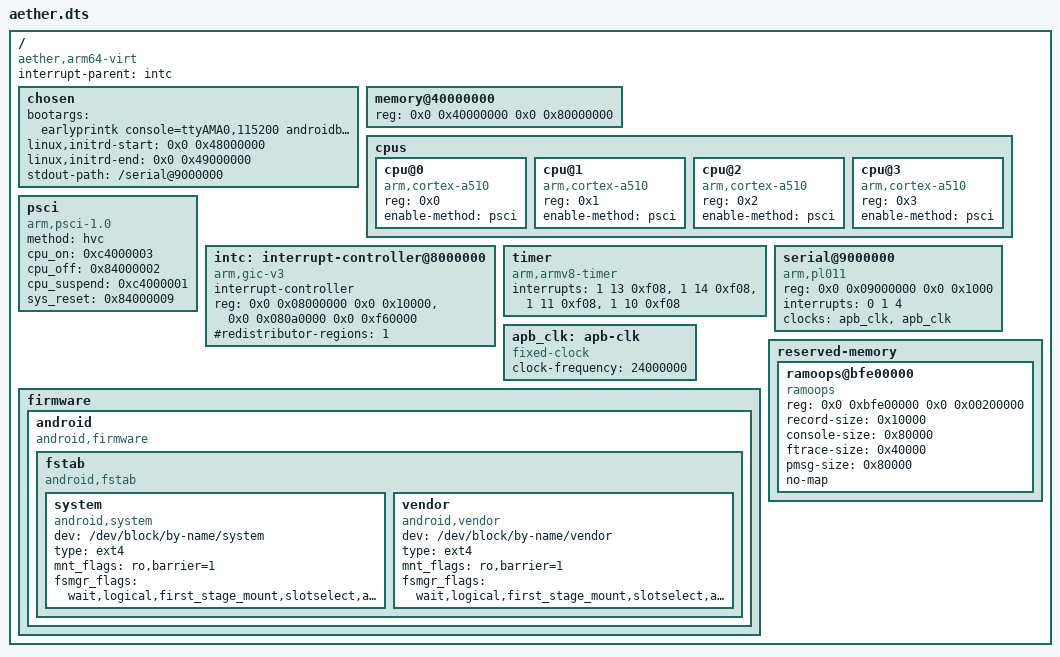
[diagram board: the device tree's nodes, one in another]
/* aether.dts — AETHER Android device tree source.
 *
 * Mirrors hypervisor/src/kernel.rs::build_production_android_dtb() output
 * with extras from hypervisor/src/kernel_defconfig.rs::ProductionDtbExtras
 * ::aether_defaults().
 *
 * Memory map matches QEMU virt machine (ARM tier). Snapdragon X Elite tier
 * uses the same layout but uart_clock_hz = 7_372_800 and the SoC's GICv3
 * base addresses.
 *
 * Source: source.android.com/devices/architecture/dto
 *         Documentation/devicetree/bindings/ in mainline kernel
 */

/dts-v1/;

/ {
    compatible = "aether,arm64-virt", "linux,dummy-virt";
    interrupt-parent = <&intc>;
    #address-cells = <2>;
    #size-cells = <2>;

    chosen {
        bootargs = "earlyprintk console=ttyAMA0,115200 androidboot.hardware=aether androidboot.selinux=enforcing androidboot.verifiedbootstate=green";
        linux,initrd-start = <0x0 0x48000000>;   /* ProductionDtbExtras.initrd_start_ipa */
        linux,initrd-end   = <0x0 0x49000000>;   /* ProductionDtbExtras.initrd_end_ipa   */
        stdout-path = "/serial@9000000";
    };

    memory@40000000 {
        device_type = "memory";
        reg = <0x0 0x40000000 0x0 0x80000000>;   /* 2 GiB DRAM at 0x40000000 */
    };

    cpus {
        #address-cells = <1>;
        #size-cells = <0>;

        cpu@0 {
            device_type = "cpu";
            compatible = "arm,cortex-a510";
            reg = <0x0>;
            enable-method = "psci";
        };
        cpu@1 {
            device_type = "cpu";
            compatible = "arm,cortex-a510";
            reg = <0x1>;
            enable-method = "psci";
        };
        cpu@2 {
            device_type = "cpu";
            compatible = "arm,cortex-a510";
            reg = <0x2>;
            enable-method = "psci";
        };
        cpu@3 {
            device_type = "cpu";
            compatible = "arm,cortex-a510";
            reg = <0x3>;
            enable-method = "psci";
        };
    };

    psci {
        compatible = "arm,psci-1.0";
        method = "hvc";
        cpu_on   = <0xc4000003>;
        cpu_off  = <0x84000002>;
        cpu_suspend = <0xc4000001>;
        sys_reset = <0x84000009>;
    };

    intc: interrupt-controller@8000000 {
        compatible = "arm,gic-v3";
        #interrupt-cells = <3>;
        interrupt-controller;
        reg = <0x0 0x08000000 0x0 0x10000>,   /* GICD */
              <0x0 0x080a0000 0x0 0xf60000>;  /* GICR — sized per ch10 */
        #redistributor-regions = <1>;
    };

    timer {
        compatible = "arm,armv8-timer";
        interrupts = <1 13 0xf08>,            /* sec PPI 13 */
                     <1 14 0xf08>,            /* non-sec PPI 14 */
                     <1 11 0xf08>,            /* virt PPI 11 */
                     <1 10 0xf08>;            /* hyp PPI 10 */
    };

    serial@9000000 {
        compatible = "arm,pl011", "arm,primecell";
        reg = <0x0 0x09000000 0x0 0x1000>;
        interrupts = <0 1 4>;                 /* SPI 1, level-high */
        clocks = <&apb_clk>, <&apb_clk>;
        clock-names = "uartclk", "apb_pclk";
    };

    apb_clk: apb-clk {
        compatible = "fixed-clock";
        #clock-cells = <0>;
        clock-frequency = <24000000>;         /* ProductionDtbExtras.uart_clock_hz */
    };

    firmware {
        android {
            compatible = "android,firmware";

            fstab {
                compatible = "android,fstab";

                system {
                    compatible = "android,system";
                    dev = "/dev/block/by-name/system";
                    type = "ext4";
                    mnt_flags = "ro,barrier=1";
                    fsmgr_flags = "wait,logical,first_stage_mount,slotselect,avb=vbmeta";
                };

                vendor {
                    compatible = "android,vendor";
                    dev = "/dev/block/by-name/vendor";
                    type = "ext4";
                    mnt_flags = "ro,barrier=1";
                    fsmgr_flags = "wait,logical,first_stage_mount,slotselect,avb=vbmeta";
                };
            };
        };
    };

    reserved-memory {
        #address-cells = <2>;
        #size-cells = <2>;
        ranges;

        ramoops@bfe00000 {
            compatible = "ramoops";
            reg = <0x0 0xbfe00000 0x0 0x00200000>;   /* base=0xBFE00000 size=2MiB */
            record-size = <0x10000>;                 /* 64 KiB */
            console-size = <0x80000>;
            ftrace-size = <0x40000>;
            pmsg-size = <0x80000>;
            no-map;
        };
    };
};
